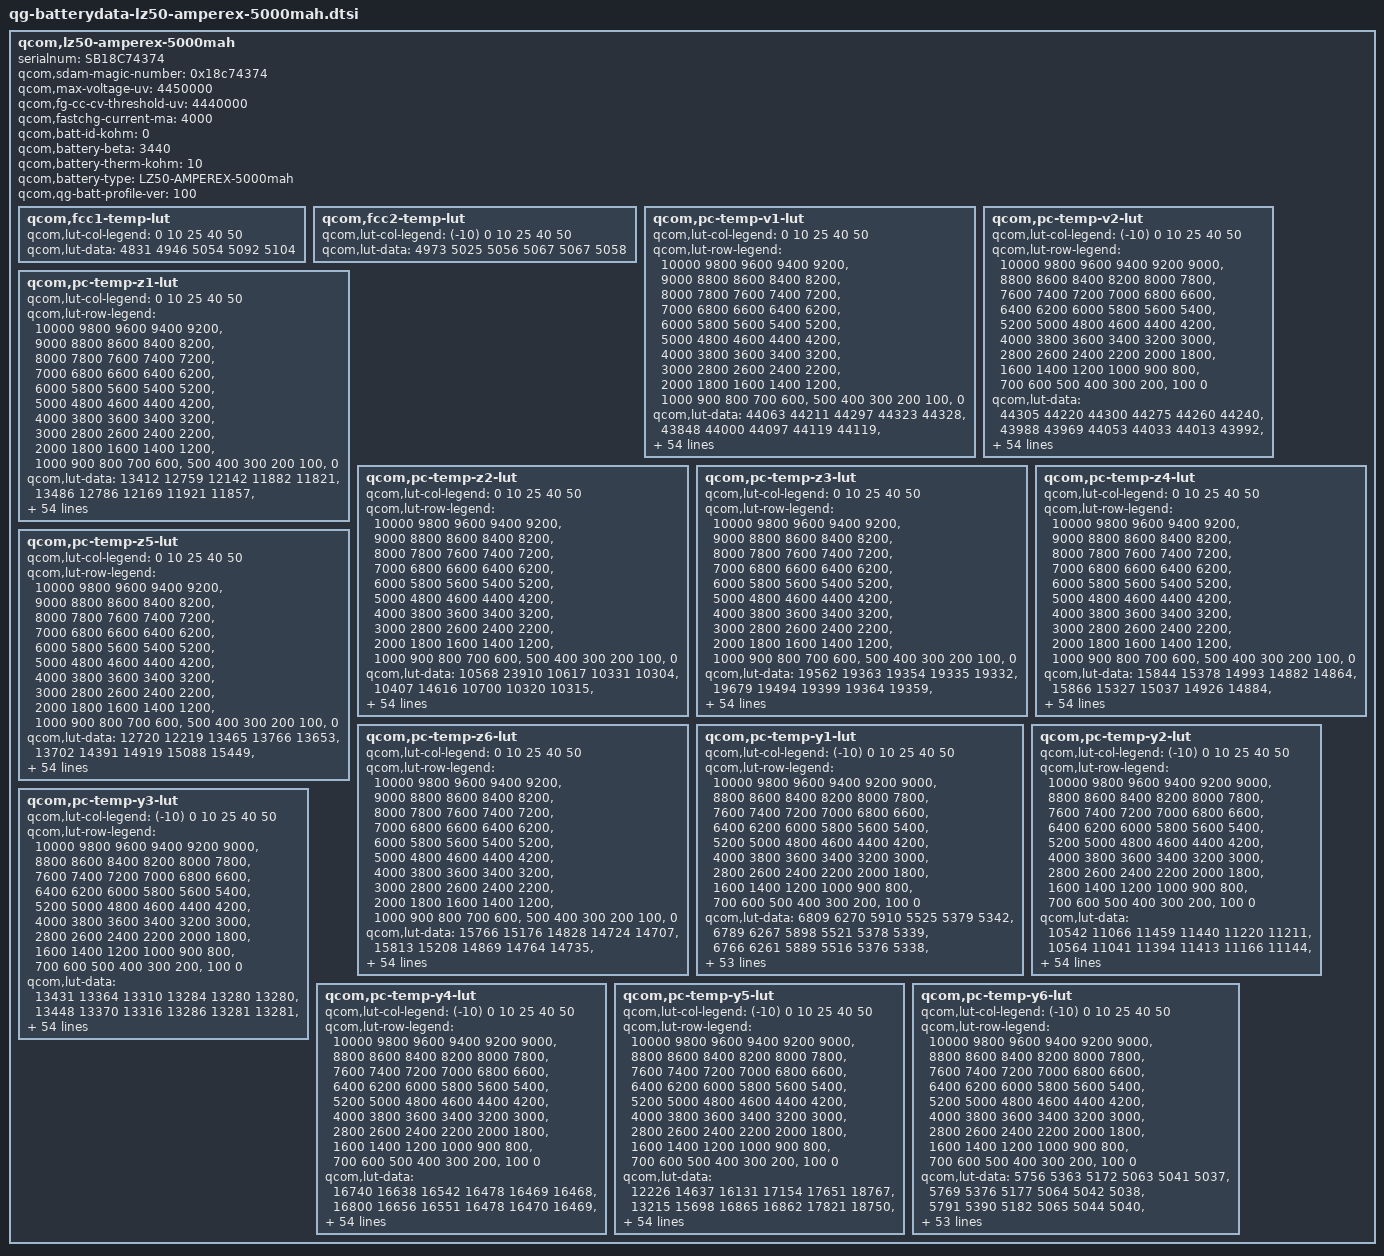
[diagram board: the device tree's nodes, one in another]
qcom,lz50-amperex-5000mah {
    /* 4458518_Lenovo_Nairobi_5000mAH_PM7250B_NEW4.45V_averaged_MasterSlave_Mar3th2020 */
    serialnum = "SB18C74374";
    qcom,sdam-magic-number = <0x18c74374>;
    qcom,max-voltage-uv = <4450000>;
    qcom,fg-cc-cv-threshold-uv = <4440000>;
    qcom,fastchg-current-ma = <4000>;
    qcom,batt-id-kohm = <0>;
    qcom,battery-beta = <3440>;
    qcom,battery-therm-kohm = <10>;
    qcom,battery-type = "LZ50-AMPEREX-5000mah";
    qcom,qg-batt-profile-ver = <100>;

	qcom,fcc1-temp-lut {
		qcom,lut-col-legend = <0 10 25 40 50>;
		qcom,lut-data = <4831 4946 5054 5092 5104>;
	};

	qcom,fcc2-temp-lut {
		qcom,lut-col-legend = <(-10) 0 10 25 40 50>;
		qcom,lut-data = <4973 5025 5056 5067 5067 5058>;
	};

	qcom,pc-temp-v1-lut {
		qcom,lut-col-legend = <0 10 25 40 50>;
		qcom,lut-row-legend = <10000 9800 9600 9400 9200>,
			<9000 8800 8600 8400 8200>,
			<8000 7800 7600 7400 7200>,
			<7000 6800 6600 6400 6200>,
			<6000 5800 5600 5400 5200>,
			<5000 4800 4600 4400 4200>,
			<4000 3800 3600 3400 3200>,
			<3000 2800 2600 2400 2200>,
			<2000 1800 1600 1400 1200>,
			<1000 900 800 700 600>,
			<500 400 300 200 100>,
			<0>;
		qcom,lut-data = <44063 44211 44297 44323 44328>,
			<43848 44000 44097 44119 44119>,
			<43627 43786 43898 43920 43917>,
			<43403 43569 43693 43715 43717>,
			<43171 43348 43475 43502 43508>,
			<42931 43117 43247 43284 43290>,
			<42691 42876 43011 43057 43065>,
			<42451 42633 42765 42818 42829>,
			<42211 42391 42519 42573 42587>,
			<41977 42149 42276 42333 42345>,
			<41747 41913 42035 42093 42101>,
			<41523 41680 41796 41854 41860>,
			<41305 41453 41561 41615 41623>,
			<41094 41233 41332 41380 41391>,
			<40887 41018 41111 41155 41167>,
			<40683 40811 40897 40936 40949>,
			<40485 40608 40690 40729 40739>,
			<40295 40413 40491 40531 40534>,
			<40112 40233 40301 40340 40339>,
			<39938 40060 40129 40160 40163>,
			<39781 39881 39951 39985 39994>,
			<39628 39696 39706 39769 39783>,
			<39456 39498 39391 39488 39487>,
			<39256 39255 39158 39243 39231>,
			<39063 38984 39019 39083 39086>,
			<38893 38813 38907 38954 38975>,
			<38740 38723 38800 38838 38858>,
			<38631 38652 38701 38735 38737>,
			<38557 38574 38607 38636 38626>,
			<38496 38498 38515 38535 38527>,
			<38440 38427 38430 38440 38438>,
			<38388 38360 38353 38357 38356>,
			<38341 38298 38281 38283 38282>,
			<38296 38243 38215 38214 38210>,
			<38254 38195 38157 38147 38137>,
			<38215 38149 38102 38082 38066>,
			<38179 38110 38051 38020 37995>,
			<38138 38068 38004 37960 37925>,
			<38076 38006 37940 37885 37841>,
			<37995 37920 37851 37785 37731>,
			<37896 37819 37748 37672 37608>,
			<37768 37699 37636 37559 37490>,
			<37621 37560 37508 37435 37364>,
			<37452 37392 37347 37273 37199>,
			<37317 37238 37198 37132 37064>,
			<37207 37137 37096 37043 36986>,
			<37166 37104 37068 37016 36957>,
			<37134 37089 37048 36994 36936>,
			<37105 37061 37030 36976 36914>,
			<37062 37024 36991 36927 36855>,
			<36912 36855 36792 36699 36603>,
			<36480 36417 36363 36263 36163>,
			<35895 35826 35785 35685 35585>,
			<35080 35000 34996 34896 34793>,
			<33673 33637 33769 33673 33565>,
			<30000 30000 30000 30000 30000>;
	};

	qcom,pc-temp-v2-lut {
		qcom,lut-col-legend = <(-10) 0 10 25 40 50>;
		qcom,lut-row-legend = <10000 9800 9600 9400 9200 9000>,
			<8800 8600 8400 8200 8000 7800>,
			<7600 7400 7200 7000 6800 6600>,
			<6400 6200 6000 5800 5600 5400>,
			<5200 5000 4800 4600 4400 4200>,
			<4000 3800 3600 3400 3200 3000>,
			<2800 2600 2400 2200 2000 1800>,
			<1600 1400 1200 1000 900 800>,
			<700 600 500 400 300 200>,
			<100 0>;
		qcom,lut-data = <44305 44220 44300 44275 44260 44240>,
			<43988 43969 44053 44033 44013 43992>,
			<43700 43729 43817 43798 43775 43754>,
			<43446 43500 43593 43573 43548 43527>,
			<43227 43286 43382 43358 43334 43313>,
			<43008 43065 43163 43136 43114 43094>,
			<42772 42826 42924 42898 42879 42862>,
			<42532 42580 42677 42655 42639 42623>,
			<42289 42335 42431 42411 42397 42383>,
			<42045 42089 42186 42165 42153 42140>,
			<41793 41850 41943 41922 41910 41899>,
			<41511 41618 41703 41683 41671 41660>,
			<41228 41392 41467 41447 41436 41426>,
			<41019 41173 41236 41216 41206 41196>,
			<40877 40961 41010 40989 40984 40972>,
			<40711 40739 40792 40770 40768 40755>,
			<40394 40497 40588 40559 40557 40547>,
			<39990 40244 40383 40356 40354 40347>,
			<39715 39989 40153 40167 40166 40161>,
			<39535 39727 39906 39988 39987 39984>,
			<39366 39488 39664 39783 39788 39788>,
			<39174 39280 39423 39529 39549 39551>,
			<38978 39092 39200 39279 39310 39313>,
			<38785 38922 39014 39070 39102 39108>,
			<38586 38766 38852 38885 38911 38919>,
			<38418 38622 38707 38732 38756 38763>,
			<38307 38491 38578 38608 38628 38635>,
			<38218 38368 38461 38498 38517 38523>,
			<38145 38248 38353 38394 38414 38416>,
			<38085 38131 38254 38297 38319 38318>,
			<38030 38036 38162 38208 38232 38229>,
			<37972 37963 38077 38126 38154 38151>,
			<37916 37903 37998 38050 38078 38075>,
			<37858 37853 37920 37983 38004 37998>,
			<37800 37812 37845 37920 37930 37919>,
			<37738 37770 37785 37850 37844 37826>,
			<37671 37728 37739 37774 37746 37710>,
			<37597 37681 37691 37693 37647 37596>,
			<37516 37618 37631 37608 37554 37498>,
			<37428 37539 37562 37519 37463 37407>,
			<37334 37441 37476 37428 37371 37316>,
			<37236 37308 37364 37334 37278 37227>,
			<37136 37164 37233 37214 37155 37103>,
			<37045 37014 37083 37074 37012 36949>,
			<36957 36893 36937 36956 36905 36850>,
			<36868 36806 36866 36899 36856 36800>,
			<36823 36771 36840 36886 36845 36791>,
			<36771 36730 36810 36868 36833 36777>,
			<36721 36676 36770 36848 36809 36751>,
			<36659 36580 36688 36791 36741 36671>,
			<36560 36333 36429 36563 36472 36363>,
			<36350 35851 35895 36067 35973 35863>,
			<35930 35143 35189 35418 35327 35208>,
			<35303 34140 34220 34507 34427 34300>,
			<34318 32755 32749 33178 33103 32919>,
			<33132 28650 27481 27771 27864 27950>;
	};

	qcom,pc-temp-z1-lut {
		qcom,lut-col-legend = <0 10 25 40 50>;
		qcom,lut-row-legend = <10000 9800 9600 9400 9200>,
			<9000 8800 8600 8400 8200>,
			<8000 7800 7600 7400 7200>,
			<7000 6800 6600 6400 6200>,
			<6000 5800 5600 5400 5200>,
			<5000 4800 4600 4400 4200>,
			<4000 3800 3600 3400 3200>,
			<3000 2800 2600 2400 2200>,
			<2000 1800 1600 1400 1200>,
			<1000 900 800 700 600>,
			<500 400 300 200 100>,
			<0>;
		qcom,lut-data = <13412 12759 12142 11882 11821>,
			<13486 12786 12169 11921 11857>,
			<13485 12797 12174 11930 11865>,
			<13479 12788 12175 11934 11870>,
			<13474 12772 12173 11935 11872>,
			<13466 12759 12168 11935 11873>,
			<13454 12748 12163 11935 11874>,
			<13434 12737 12156 11935 11876>,
			<13407 12728 12151 11935 11879>,
			<13390 12720 12148 11936 11882>,
			<13367 12715 12146 11939 11887>,
			<13350 12702 12146 11942 11891>,
			<13343 12691 12149 11945 11895>,
			<13326 12689 12150 11947 11898>,
			<13312 12686 12150 11948 11900>,
			<13291 12685 12149 11949 11902>,
			<13267 12682 12149 11950 11903>,
			<13251 12680 12150 11951 11905>,
			<13236 12677 12150 11953 11907>,
			<13230 12674 12153 11955 11910>,
			<13239 12674 12156 11957 11912>,
			<13254 12675 12157 11958 11913>,
			<13258 12678 12158 11959 11915>,
			<13259 12681 12160 11960 11916>,
			<13259 12686 12163 11962 11919>,
			<13259 12692 12169 11966 11922>,
			<13258 12700 12173 11969 11925>,
			<13258 12707 12177 11974 11929>,
			<13259 12709 12182 11978 11932>,
			<13262 12709 12187 11981 11936>,
			<13264 12711 12193 11985 11940>,
			<13268 12718 12199 11989 11944>,
			<13273 12728 12205 11994 11948>,
			<13290 12735 12211 12000 11952>,
			<13312 12741 12218 12005 11957>,
			<13319 12749 12224 12010 11962>,
			<13323 12759 12231 12014 11966>,
			<13328 12769 12238 12018 11969>,
			<13342 12778 12244 12022 11973>,
			<13368 12787 12250 12026 11976>,
			<13389 12796 12256 12030 11979>,
			<13404 12815 12264 12034 11982>,
			<13429 12837 12271 12038 11985>,
			<13482 12856 12279 12042 11989>,
			<13503 12877 12289 12047 11992>,
			<13497 12866 12297 12050 11994>,
			<13518 12865 12297 12051 11995>,
			<13485 12874 12295 12050 11995>,
			<13529 12871 12298 12051 11997>,
			<13520 12898 12308 12055 11999>,
			<13532 12898 12315 12060 12003>,
			<13562 12916 12328 12068 12010>,
			<13582 12959 12340 12078 12020>,
			<13616 12973 12365 12094 12035>,
			<13616 12973 12365 12094 12035>,
			<13616 12973 12365 12094 12035>;
	};

	qcom,pc-temp-z2-lut {
		qcom,lut-col-legend = <0 10 25 40 50>;
		qcom,lut-row-legend = <10000 9800 9600 9400 9200>,
			<9000 8800 8600 8400 8200>,
			<8000 7800 7600 7400 7200>,
			<7000 6800 6600 6400 6200>,
			<6000 5800 5600 5400 5200>,
			<5000 4800 4600 4400 4200>,
			<4000 3800 3600 3400 3200>,
			<3000 2800 2600 2400 2200>,
			<2000 1800 1600 1400 1200>,
			<1000 900 800 700 600>,
			<500 400 300 200 100>,
			<0>;
		qcom,lut-data = <10568 23910 10617 10331 10304>,
			<10407 14616 10700 10320 10315>,
			<10371 10559 11111 10418 10395>,
			<10347 10523 11352 10548 10485>,
			<10320 10499 11266 10556 10496>,
			<10292 10475 11090 10522 10471>,
			<10272 10450 10891 10487 10445>,
			<10259 10434 10628 10451 10424>,
			<10250 10425 10504 10421 10402>,
			<10248 10419 10626 10548 10380>,
			<10251 10419 10789 10873 10355>,
			<10255 10420 10757 10948 10347>,
			<10263 10423 10572 10658 10359>,
			<10278 10431 10491 10414 10374>,
			<10293 10447 10653 10410 10372>,
			<10306 10467 10860 10413 10364>,
			<10322 10496 10931 10475 10366>,
			<10345 10526 10972 10894 10401>,
			<10382 10551 10982 11198 10434>,
			<10417 10573 10808 10959 10412>,
			<10448 10579 10618 10566 10363>,
			<10476 10576 10631 10871 10373>,
			<10488 10574 10701 12811 10539>,
			<10493 10582 10728 14011 10663>,
			<10499 10604 10641 12626 10565>,
			<10507 10611 10544 10638 10389>,
			<10516 10597 10555 10358 10422>,
			<10524 10583 10611 10439 10834>,
			<10529 10588 10647 10515 11102>,
			<10534 10608 10668 10607 10955>,
			<10541 10619 10680 10697 10693>,
			<10552 10621 10674 10678 10533>,
			<10562 10623 10656 10563 10416>,
			<10570 10625 10645 10488 10334>,
			<10577 10627 10637 10461 10271>,
			<10585 10629 10632 10446 10231>,
			<10592 10634 10642 10463 10244>,
			<10600 10642 10671 10522 10309>,
			<10614 10655 10704 10586 10390>,
			<10633 10677 10749 10673 10529>,
			<10652 10697 10785 10735 10643>,
			<10670 10708 10797 10734 10661>,
			<10699 10722 10804 10728 10669>,
			<10766 10757 10812 10733 10680>,
			<10928 10967 10863 10722 10666>,
			<10936 11130 10928 10674 10529>,
			<10854 11157 10914 10589 10461>,
			<10782 11774 10906 10565 10469>,
			<10794 11874 10916 10607 10506>,
			<10689 11916 10982 10704 10605>,
			<10661 11929 10971 10609 10493>,
			<10573 11540 10906 10437 10234>,
			<10323 11311 10807 10297 10160>,
			<10164 11003 10728 10226 10078>,
			<10164 11003 10728 10226 10078>,
			<10164 11003 10728 10226 10078>;
	};

	qcom,pc-temp-z3-lut {
		qcom,lut-col-legend = <0 10 25 40 50>;
		qcom,lut-row-legend = <10000 9800 9600 9400 9200>,
			<9000 8800 8600 8400 8200>,
			<8000 7800 7600 7400 7200>,
			<7000 6800 6600 6400 6200>,
			<6000 5800 5600 5400 5200>,
			<5000 4800 4600 4400 4200>,
			<4000 3800 3600 3400 3200>,
			<3000 2800 2600 2400 2200>,
			<2000 1800 1600 1400 1200>,
			<1000 900 800 700 600>,
			<500 400 300 200 100>,
			<0>;
		qcom,lut-data = <19562 19363 19354 19335 19332>,
			<19679 19494 19399 19364 19359>,
			<19741 19565 19421 19385 19388>,
			<19780 19583 19438 19411 19404>,
			<19794 19594 19460 19422 19414>,
			<19800 19600 19480 19428 19421>,
			<19803 19603 19482 19433 19426>,
			<19803 19604 19477 19438 19431>,
			<19801 19601 19475 19442 19434>,
			<19800 19594 19484 19450 19435>,
			<19796 19588 19495 19458 19436>,
			<19790 19583 19489 19458 19435>,
			<19781 19578 19464 19444 19431>,
			<19770 19573 19450 19428 19424>,
			<19764 19568 19454 19421 19418>,
			<19765 19562 19459 19414 19411>,
			<19765 19556 19457 19410 19405>,
			<19760 19550 19452 19411 19400>,
			<19742 19543 19445 19411 19395>,
			<19729 19537 19431 19402 19386>,
			<19726 19535 19419 19388 19377>,
			<19725 19545 19425 19384 19375>,
			<19727 19557 19447 19387 19379>,
			<19739 19567 19456 19389 19383>,
			<19749 19576 19438 19377 19369>,
			<19749 19578 19416 19359 19345>,
			<19748 19565 19408 19356 19348>,
			<19746 19551 19403 19358 19401>,
			<19738 19546 19401 19362 19437>,
			<19728 19543 19407 19388 19435>,
			<19720 19543 19415 19419 19429>,
			<19713 19547 19424 19422 19422>,
			<19708 19552 19433 19416 19411>,
			<19704 19552 19436 19409 19399>,
			<19701 19551 19435 19401 19387>,
			<19698 19550 19433 19391 19377>,
			<19695 19548 19429 19383 19369>,
			<19691 19545 19422 19375 19362>,
			<19685 19542 19419 19373 19360>,
			<19677 19537 19418 19374 19360>,
			<19669 19532 19417 19375 19360>,
			<19659 19526 19412 19375 19362>,
			<19645 19519 19406 19373 19368>,
			<19622 19509 19402 19377 19376>,
			<19386 19473 19393 19376 19375>,
			<19307 19439 19384 19363 19359>,
			<19304 19429 19379 19351 19348>,
			<19298 19299 19376 19349 19337>,
			<19294 19291 19363 19339 19331>,
			<19293 19285 19355 19333 19327>,
			<19293 19296 19372 19349 19343>,
			<19303 19309 19379 19380 19370>,
			<19311 19322 19383 19379 19371>,
			<19327 19384 19387 19380 19375>,
			<19327 19384 19387 19380 19375>,
			<19327 19384 19387 19380 19375>;
	};

	qcom,pc-temp-z4-lut {
		qcom,lut-col-legend = <0 10 25 40 50>;
		qcom,lut-row-legend = <10000 9800 9600 9400 9200>,
			<9000 8800 8600 8400 8200>,
			<8000 7800 7600 7400 7200>,
			<7000 6800 6600 6400 6200>,
			<6000 5800 5600 5400 5200>,
			<5000 4800 4600 4400 4200>,
			<4000 3800 3600 3400 3200>,
			<3000 2800 2600 2400 2200>,
			<2000 1800 1600 1400 1200>,
			<1000 900 800 700 600>,
			<500 400 300 200 100>,
			<0>;
		qcom,lut-data = <15844 15378 14993 14882 14864>,
			<15866 15327 15037 14926 14884>,
			<15745 15267 14997 14914 14880>,
			<15556 15190 14949 14889 14864>,
			<15423 15106 14902 14866 14847>,
			<15316 15040 14860 14842 14827>,
			<15228 14986 14838 14819 14807>,
			<15156 14942 14824 14800 14789>,
			<15096 14908 14810 14780 14772>,
			<15046 14881 14775 14751 14755>,
			<15002 14857 14736 14717 14739>,
			<14966 14837 14729 14704 14727>,
			<14939 14819 14735 14709 14718>,
			<14917 14802 14735 14713 14711>,
			<14896 14787 14716 14711 14707>,
			<14870 14776 14693 14707 14705>,
			<14849 14767 14685 14700 14701>,
			<14841 14761 14681 14682 14697>,
			<14837 14755 14678 14669 14693>,
			<14831 14751 14683 14670 14690>,
			<14808 14748 14694 14679 14687>,
			<14778 14746 14721 14696 14693>,
			<14773 14745 14782 14753 14760>,
			<14788 14770 14822 14805 14821>,
			<14807 14834 14840 14832 14836>,
			<14830 14858 14849 14850 14845>,
			<14855 14852 14847 14850 14835>,
			<14863 14841 14835 14834 14764>,
			<14858 14830 14820 14811 14711>,
			<14849 14816 14800 14768 14702>,
			<14840 14801 14778 14722 14696>,
			<14828 14784 14755 14706 14692>,
			<14817 14768 14733 14697 14687>,
			<14806 14757 14718 14693 14685>,
			<14794 14749 14708 14691 14685>,
			<14784 14742 14703 14690 14684>,
			<14773 14735 14701 14690 14684>,
			<14763 14730 14700 14690 14683>,
			<14754 14728 14701 14690 14684>,
			<14745 14727 14707 14700 14698>,
			<14736 14725 14712 14710 14712>,
			<14728 14717 14710 14708 14707>,
			<14719 14707 14708 14703 14696>,
			<14708 14699 14705 14701 14696>,
			<14857 14681 14691 14691 14689>,
			<14913 14676 14671 14673 14669>,
			<14913 14678 14666 14678 14673>,
			<14915 14816 14654 14666 14668>,
			<14915 14820 14651 14653 14651>,
			<14910 14823 14652 14644 14638>,
			<14906 14814 14654 14663 14667>,
			<14918 14816 14667 14659 14669>,
			<14923 14812 14668 14667 14676>,
			<14931 14758 14669 14670 14677>,
			<14931 14758 14669 14670 14677>,
			<14931 14758 14669 14670 14677>;
	};

	qcom,pc-temp-z5-lut {
		qcom,lut-col-legend = <0 10 25 40 50>;
		qcom,lut-row-legend = <10000 9800 9600 9400 9200>,
			<9000 8800 8600 8400 8200>,
			<8000 7800 7600 7400 7200>,
			<7000 6800 6600 6400 6200>,
			<6000 5800 5600 5400 5200>,
			<5000 4800 4600 4400 4200>,
			<4000 3800 3600 3400 3200>,
			<3000 2800 2600 2400 2200>,
			<2000 1800 1600 1400 1200>,
			<1000 900 800 700 600>,
			<500 400 300 200 100>,
			<0>;
		qcom,lut-data = <12720 12219 13465 13766 13653>,
			<13702 14391 14919 15088 15449>,
			<14339 15698 15683 16499 17678>,
			<14837 16198 16331 18254 19178>,
			<15243 16541 17411 19083 20295>,
			<15562 16948 18592 19545 21140>,
			<15894 17415 19061 20042 22025>,
			<16305 17839 19304 20796 23113>,
			<16775 18167 19624 21824 24284>,
			<17297 18463 22025 24177 25594>,
			<17912 18830 24905 27887 27230>,
			<18525 19302 24701 29049 28711>,
			<19011 19848 22588 27310 30133>,
			<19442 20463 21605 25803 31114>,
			<20115 21163 24131 25845 31090>,
			<21865 21938 27699 26041 30776>,
			<23548 22958 29310 27003 30797>,
			<23763 23706 30335 30821 32108>,
			<23664 23773 30709 33690 33341>,
			<23621 23649 28174 32058 32794>,
			<25288 24066 25495 29067 31608>,
			<29061 28972 30028 29094 31488>,
			<34120 35195 44125 30734 32532>,
			<43090 39493 49979 31816 32771>,
			<49235 43396 38533 27314 27268>,
			<48960 44144 24809 19647 18572>,
			<47580 37180 21199 17390 17980>,
			<45700 29438 19407 16731 25963>,
			<41886 27492 18948 16546 32190>,
			<38063 26514 19336 20259 33201>,
			<36375 26306 20095 25617 33150>,
			<35246 27933 21599 27316 32237>,
			<34849 30388 24332 28094 30962>,
			<35192 32347 27029 28419 29801>,
			<35823 34336 30122 28545 28688>,
			<36405 35791 32263 28609 27858>,
			<37123 36928 32572 28532 27642>,
			<37856 37732 32682 28285 27553>,
			<38833 37839 32748 28250 27549>,
			<39943 37637 32809 29282 27726>,
			<40158 37287 32783 30263 27900>,
			<39152 36230 30399 28259 27521>,
			<38082 35157 26948 24800 26813>,
			<37022 34628 26662 27218 30735>,
			<18425 34080 27594 28400 32321>,
			<12720 28098 28184 25227 25615>,
			<12589 25496 26086 20797 20759>,
			<12419 12685 26593 21526 18845>,
			<12324 12448 22891 21445 20182>,
			<12318 12310 21364 22307 22825>,
			<12441 12709 25154 23609 23796>,
			<12520 12986 21342 25363 23502>,
			<12517 13249 20910 22007 20409>,
			<12862 17533 20320 19796 18684>,
			<12862 17533 20320 19796 18684>,
			<12862 17533 20320 19796 18684>;
	};

	qcom,pc-temp-z6-lut {
		qcom,lut-col-legend = <0 10 25 40 50>;
		qcom,lut-row-legend = <10000 9800 9600 9400 9200>,
			<9000 8800 8600 8400 8200>,
			<8000 7800 7600 7400 7200>,
			<7000 6800 6600 6400 6200>,
			<6000 5800 5600 5400 5200>,
			<5000 4800 4600 4400 4200>,
			<4000 3800 3600 3400 3200>,
			<3000 2800 2600 2400 2200>,
			<2000 1800 1600 1400 1200>,
			<1000 900 800 700 600>,
			<500 400 300 200 100>,
			<0>;
		qcom,lut-data = <15766 15176 14828 14724 14707>,
			<15813 15208 14869 14764 14735>,
			<15770 15219 14864 14772 14748>,
			<15698 15198 14859 14776 14752>,
			<15637 15155 14852 14774 14752>,
			<15581 15122 14842 14767 14748>,
			<15530 15095 14833 14760 14743>,
			<15488 15071 14823 14754 14738>,
			<15451 15049 14814 14749 14733>,
			<15418 15030 14804 14742 14728>,
			<15389 15013 14794 14734 14723>,
			<15364 14998 14785 14728 14718>,
			<15341 14984 14776 14721 14712>,
			<15320 14973 14768 14715 14706>,
			<15302 14962 14761 14710 14701>,
			<15286 14953 14755 14705 14696>,
			<15271 14944 14750 14699 14691>,
			<15256 14936 14745 14693 14687>,
			<15242 14930 14741 14688 14682>,
			<15229 14925 14737 14683 14676>,
			<15215 14924 14734 14679 14669>,
			<15202 14927 14746 14683 14671>,
			<15202 14935 14788 14714 14705>,
			<15215 14954 14806 14738 14731>,
			<15230 14987 14804 14739 14728>,
			<15242 14998 14800 14738 14722>,
			<15253 14990 14795 14735 14719>,
			<15256 14979 14789 14730 14717>,
			<15251 14972 14783 14725 14715>,
			<15244 14966 14779 14722 14712>,
			<15237 14961 14774 14718 14706>,
			<15230 14958 14770 14714 14701>,
			<15224 14954 14766 14708 14694>,
			<15219 14952 14762 14703 14688>,
			<15215 14949 14759 14698 14682>,
			<15212 14947 14756 14694 14677>,
			<15210 14946 14753 14689 14672>,
			<15209 14945 14750 14685 14668>,
			<15209 14945 14750 14684 14667>,
			<15211 14947 14753 14689 14673>,
			<15213 14948 14755 14694 14679>,
			<15215 14946 14754 14693 14678>,
			<15216 14943 14750 14690 14677>,
			<15212 14941 14749 14692 14681>,
			<15173 14923 14740 14688 14678>,
			<15160 14907 14728 14674 14662>,
			<15159 14903 14723 14670 14658>,
			<15158 14897 14716 14663 14650>,
			<15158 14897 14709 14653 14639>,
			<15162 14899 14707 14645 14631>,
			<15171 14907 14718 14663 14653>,
			<15189 14922 14730 14680 14671>,
			<15207 14934 14736 14685 14677>,
			<15238 14955 14743 14691 14684>,
			<15238 14955 14743 14691 14684>,
			<15238 14955 14743 14691 14684>;
	};

	qcom,pc-temp-y1-lut {
		qcom,lut-col-legend = <(-10) 0 10 25 40 50>;
		qcom,lut-row-legend = <10000 9800 9600 9400 9200 9000>,
			<8800 8600 8400 8200 8000 7800>,
			<7600 7400 7200 7000 6800 6600>,
			<6400 6200 6000 5800 5600 5400>,
			<5200 5000 4800 4600 4400 4200>,
			<4000 3800 3600 3400 3200 3000>,
			<2800 2600 2400 2200 2000 1800>,
			<1600 1400 1200 1000 900 800>,
			<700 600 500 400 300 200>,
			<100 0>;
		qcom,lut-data = <6809 6270 5910 5525 5379 5342>,
			<6789 6267 5898 5521 5378 5339>,
			<6766 6261 5889 5516 5376 5338>,
			<6745 6255 5882 5512 5374 5337>,
			<6730 6249 5878 5508 5373 5337>,
			<6724 6245 5876 5505 5372 5337>,
			<6727 6241 5877 5503 5371 5337>,
			<6733 6237 5880 5501 5371 5338>,
			<6737 6237 5879 5500 5371 5338>,
			<6742 6238 5877 5499 5370 5338>,
			<6747 6239 5875 5498 5370 5338>,
			<6751 6240 5868 5497 5371 5338>,
			<6757 6242 5862 5496 5371 5339>,
			<6759 6242 5861 5496 5371 5340>,
			<6759 6241 5861 5496 5372 5341>,
			<6760 6241 5862 5497 5372 5341>,
			<6763 6244 5862 5498 5373 5342>,
			<6766 6247 5863 5499 5374 5343>,
			<6766 6248 5864 5500 5376 5344>,
			<6758 6248 5865 5501 5378 5346>,
			<6751 6249 5866 5503 5380 5348>,
			<6759 6246 5867 5505 5381 5349>,
			<6772 6243 5867 5508 5381 5351>,
			<6775 6246 5869 5511 5383 5352>,
			<6777 6253 5872 5514 5385 5353>,
			<6778 6256 5873 5516 5386 5354>,
			<6772 6252 5875 5519 5388 5356>,
			<6761 6246 5876 5522 5390 5358>,
			<6754 6244 5877 5525 5392 5360>,
			<6750 6242 5879 5528 5395 5363>,
			<6748 6242 5880 5531 5398 5365>,
			<6751 6246 5882 5535 5400 5367>,
			<6755 6250 5883 5538 5403 5369>,
			<6756 6250 5885 5541 5405 5371>,
			<6759 6249 5888 5544 5407 5373>,
			<6761 6250 5891 5547 5409 5375>,
			<6765 6254 5897 5550 5410 5376>,
			<6772 6260 5901 5552 5411 5378>,
			<6774 6265 5906 5552 5412 5379>,
			<6772 6272 5910 5552 5413 5381>,
			<6770 6274 5911 5553 5414 5382>,
			<6769 6268 5906 5555 5415 5383>,
			<6769 6267 5908 5558 5416 5384>,
			<6768 6271 5917 5561 5418 5385>,
			<6778 6274 5940 5565 5420 5387>,
			<6836 6305 5949 5569 5423 5390>,
			<6859 6314 5942 5570 5424 5390>,
			<6855 6314 5953 5570 5424 5390>,
			<6855 6322 5956 5571 5425 5391>,
			<6883 6324 5959 5572 5425 5392>,
			<6916 6334 5972 5573 5427 5395>,
			<6981 6412 5991 5579 5432 5399>,
			<7110 6503 6010 5591 5440 5406>,
			<7322 6717 6073 5605 5450 5417>,
			<7322 6717 6073 5605 5450 5417>,
			<7322 6717 6073 5605 5450 5417>;
	};

	qcom,pc-temp-y2-lut {
		qcom,lut-col-legend = <(-10) 0 10 25 40 50>;
		qcom,lut-row-legend = <10000 9800 9600 9400 9200 9000>,
			<8800 8600 8400 8200 8000 7800>,
			<7600 7400 7200 7000 6800 6600>,
			<6400 6200 6000 5800 5600 5400>,
			<5200 5000 4800 4600 4400 4200>,
			<4000 3800 3600 3400 3200 3000>,
			<2800 2600 2400 2200 2000 1800>,
			<1600 1400 1200 1000 900 800>,
			<700 600 500 400 300 200>,
			<100 0>;
		qcom,lut-data = <10542 11066 11459 11440 11220 11211>,
			<10564 11041 11394 11413 11166 11144>,
			<10605 11015 11331 11378 11110 11062>,
			<10652 10990 11272 11341 11057 10980>,
			<10691 10969 11221 11304 11009 10911>,
			<10710 10955 11179 11272 10970 10872>,
			<10711 10946 11143 11239 10934 10854>,
			<10712 10940 11115 11208 10905 10841>,
			<10709 10939 11093 11184 10888 10826>,
			<10694 10940 11075 11164 10875 10798>,
			<10684 10943 11069 11152 10871 10783>,
			<10754 10953 11071 11142 10877 10786>,
			<10875 10973 11077 11135 10887 10792>,
			<10903 11001 11091 11136 10890 10795>,
			<10898 11045 11126 11141 10890 10795>,
			<10894 11078 11163 11149 10900 10801>,
			<10905 11092 11201 11173 10937 10823>,
			<10932 11103 11236 11211 10990 10857>,
			<10958 11124 11258 11272 11042 10898>,
			<10987 11157 11274 11358 11100 10954>,
			<11005 11189 11292 11394 11169 11023>,
			<11004 11214 11317 11401 11283 11140>,
			<11000 11236 11346 11406 11364 11228>,
			<10918 11254 11374 11411 11336 11207>,
			<10293 11271 11403 11418 11268 11144>,
			<9767 11283 11426 11427 11242 11124>,
			<9725 11290 11447 11451 11248 11152>,
			<9708 11297 11461 11477 11266 11191>,
			<9698 11311 11468 11502 11321 11216>,
			<9692 11335 11474 11530 11415 11241>,
			<9687 11351 11477 11552 11463 11289>,
			<9682 11361 11481 11585 11483 11431>,
			<9678 11366 11485 11606 11502 11552>,
			<9674 11342 11489 11614 11532 11583>,
			<9671 11262 11493 11621 11562 11602>,
			<9669 11183 11491 11617 11550 11588>,
			<9667 11118 11464 11595 11454 11474>,
			<9666 11050 11429 11567 11390 11375>,
			<9665 10979 11397 11523 11389 11347>,
			<9664 10901 11360 11480 11389 11330>,
			<9663 10746 11315 11476 11387 11324>,
			<9662 10149 11258 11489 11369 11331>,
			<9662 9783 11187 11487 11333 11294>,
			<9661 9719 11095 11478 11266 11179>,
			<9660 9692 10987 11478 11169 11016>,
			<9659 9681 10962 11379 11050 10907>,
			<9659 9674 10879 11326 11052 10949>,
			<9658 9669 10816 11287 11071 10981>,
			<9657 9665 10728 11287 11082 10968>,
			<9656 9661 10651 11316 11080 10975>,
			<9653 9657 10496 11316 11035 10854>,
			<9649 9652 10039 11251 10948 10806>,
			<9648 9650 9684 11154 10833 10671>,
			<9648 9649 9655 10989 10671 10534>,
			<9648 9649 9655 10989 10671 10534>,
			<9648 9649 9655 10989 10671 10534>;
	};

	qcom,pc-temp-y3-lut {
		qcom,lut-col-legend = <(-10) 0 10 25 40 50>;
		qcom,lut-row-legend = <10000 9800 9600 9400 9200 9000>,
			<8800 8600 8400 8200 8000 7800>,
			<7600 7400 7200 7000 6800 6600>,
			<6400 6200 6000 5800 5600 5400>,
			<5200 5000 4800 4600 4400 4200>,
			<4000 3800 3600 3400 3200 3000>,
			<2800 2600 2400 2200 2000 1800>,
			<1600 1400 1200 1000 900 800>,
			<700 600 500 400 300 200>,
			<100 0>;
		qcom,lut-data = <13431 13364 13310 13284 13280 13280>,
			<13448 13370 13316 13286 13281 13281>,
			<13469 13379 13322 13288 13282 13281>,
			<13491 13389 13327 13290 13284 13282>,
			<13509 13398 13332 13291 13285 13283>,
			<13520 13402 13333 13291 13286 13284>,
			<13524 13403 13332 13291 13286 13285>,
			<13527 13404 13331 13291 13287 13286>,
			<13527 13404 13331 13292 13287 13286>,
			<13523 13403 13334 13294 13288 13287>,
			<13517 13402 13336 13296 13288 13287>,
			<13510 13401 13337 13298 13289 13288>,
			<13502 13400 13338 13300 13289 13288>,
			<13494 13401 13338 13301 13290 13288>,
			<13484 13406 13339 13300 13294 13288>,
			<13474 13408 13339 13300 13296 13289>,
			<13463 13401 13342 13302 13296 13291>,
			<13452 13389 13345 13305 13297 13294>,
			<13449 13383 13344 13305 13298 13296>,
			<13448 13379 13340 13305 13299 13298>,
			<13447 13375 13336 13304 13299 13299>,
			<13443 13370 13332 13303 13296 13295>,
			<13433 13366 13327 13300 13291 13289>,
			<13420 13363 13324 13296 13288 13285>,
			<13399 13360 13320 13290 13285 13282>,
			<13385 13358 13319 13288 13283 13281>,
			<13384 13355 13318 13289 13282 13281>,
			<13384 13353 13318 13291 13282 13282>,
			<13386 13348 13317 13291 13282 13281>,
			<13400 13339 13317 13291 13282 13279>,
			<13419 13333 13317 13291 13282 13279>,
			<13438 13330 13317 13291 13282 13279>,
			<13460 13328 13317 13292 13282 13280>,
			<13488 13330 13316 13292 13283 13281>,
			<13526 13337 13314 13293 13283 13283>,
			<13571 13345 13314 13293 13284 13283>,
			<13618 13354 13316 13293 13283 13282>,
			<13669 13362 13318 13292 13282 13281>,
			<13725 13368 13320 13292 13283 13281>,
			<13789 13372 13322 13291 13284 13283>,
			<13855 13376 13323 13291 13285 13284>,
			<13919 13379 13325 13291 13286 13286>,
			<13987 13385 13326 13291 13285 13285>,
			<14071 13415 13327 13289 13282 13280>,
			<14172 13453 13325 13288 13281 13282>,
			<14245 13470 13326 13289 13289 13287>,
			<14289 13518 13331 13294 13293 13292>,
			<14404 13582 13337 13299 13297 13294>,
			<14567 13688 13347 13306 13299 13295>,
			<14798 13878 13363 13307 13298 13294>,
			<15459 14252 13374 13303 13293 13289>,
			<18231 15579 13391 13299 13291 13289>,
			<27781 21530 13563 13303 13295 13292>,
			<65535 44415 14908 13310 13304 13302>,
			<65535 44415 14908 13310 13304 13302>,
			<65535 44415 14908 13310 13304 13302>;
	};

	qcom,pc-temp-y4-lut {
		qcom,lut-col-legend = <(-10) 0 10 25 40 50>;
		qcom,lut-row-legend = <10000 9800 9600 9400 9200 9000>,
			<8800 8600 8400 8200 8000 7800>,
			<7600 7400 7200 7000 6800 6600>,
			<6400 6200 6000 5800 5600 5400>,
			<5200 5000 4800 4600 4400 4200>,
			<4000 3800 3600 3400 3200 3000>,
			<2800 2600 2400 2200 2000 1800>,
			<1600 1400 1200 1000 900 800>,
			<700 600 500 400 300 200>,
			<100 0>;
		qcom,lut-data = <16740 16638 16542 16478 16469 16468>,
			<16800 16656 16551 16478 16470 16469>,
			<16890 16692 16559 16479 16470 16471>,
			<16987 16735 16566 16481 16471 16473>,
			<17068 16770 16573 16484 16473 16475>,
			<17110 16785 16579 16486 16474 16476>,
			<17120 16786 16583 16491 16475 16476>,
			<17125 16786 16587 16496 16477 16475>,
			<17134 16789 16590 16499 16479 16476>,
			<17146 16797 16594 16501 16481 16477>,
			<17153 16808 16599 16502 16484 16479>,
			<17142 16826 16609 16505 16488 16481>,
			<17124 16848 16623 16510 16493 16484>,
			<17136 16867 16640 16517 16495 16487>,
			<17246 16887 16661 16529 16497 16492>,
			<17327 16896 16685 16541 16500 16496>,
			<17206 16890 16720 16554 16507 16499>,
			<16979 16877 16747 16568 16517 16503>,
			<16907 16844 16739 16596 16535 16513>,
			<16899 16763 16701 16636 16561 16531>,
			<16890 16703 16660 16646 16569 16538>,
			<16853 16678 16610 16599 16555 16531>,
			<16801 16660 16568 16542 16535 16520>,
			<16788 16644 16550 16512 16510 16503>,
			<16793 16631 16539 16488 16481 16480>,
			<16799 16620 16535 16483 16473 16473>,
			<16806 16610 16533 16484 16475 16474>,
			<16813 16601 16533 16485 16479 16475>,
			<16817 16591 16534 16488 16484 16479>,
			<16818 16579 16536 16494 16492 16488>,
			<16820 16575 16537 16501 16501 16497>,
			<16824 16579 16537 16507 16513 16506>,
			<16832 16587 16537 16514 16522 16514>,
			<16838 16595 16533 16523 16525 16520>,
			<16843 16604 16526 16532 16527 16524>,
			<16846 16616 16525 16532 16525 16523>,
			<16849 16635 16532 16522 16512 16505>,
			<16852 16655 16542 16510 16500 16492>,
			<16852 16672 16551 16499 16494 16492>,
			<16848 16687 16561 16489 16490 16494>,
			<16844 16704 16568 16489 16491 16498>,
			<16841 16731 16573 16494 16497 16510>,
			<16840 16740 16576 16492 16492 16505>,
			<16843 16718 16577 16481 16471 16471>,
			<16857 16712 16569 16469 16459 16454>,
			<16862 16710 16559 16477 16467 16479>,
			<16855 16724 16576 16491 16497 16515>,
			<16873 16749 16601 16516 16536 16558>,
			<16893 16789 16638 16555 16579 16599>,
			<16914 16838 16684 16583 16597 16609>,
			<16968 16852 16689 16545 16525 16513>,
			<17310 16939 16699 16492 16484 16489>,
			<18791 18479 16782 16495 16486 16489>,
			<29455 38235 17022 16515 16492 16492>,
			<29455 38235 17022 16515 16492 16492>,
			<29455 38235 17022 16515 16492 16492>;
	};

	qcom,pc-temp-y5-lut {
		qcom,lut-col-legend = <(-10) 0 10 25 40 50>;
		qcom,lut-row-legend = <10000 9800 9600 9400 9200 9000>,
			<8800 8600 8400 8200 8000 7800>,
			<7600 7400 7200 7000 6800 6600>,
			<6400 6200 6000 5800 5600 5400>,
			<5200 5000 4800 4600 4400 4200>,
			<4000 3800 3600 3400 3200 3000>,
			<2800 2600 2400 2200 2000 1800>,
			<1600 1400 1200 1000 900 800>,
			<700 600 500 400 300 200>,
			<100 0>;
		qcom,lut-data = <12226 14637 16131 17154 17651 18767>,
			<13215 15698 16865 16862 17821 18750>,
			<14204 16531 17301 16548 17836 18564>,
			<15129 17131 17513 16230 17732 18302>,
			<15930 17493 17572 15928 17539 18057>,
			<16542 17611 17546 15660 17292 17923>,
			<17047 17411 16787 15121 16925 17787>,
			<17424 17035 15689 14513 16497 17596>,
			<17472 16695 15329 14421 16137 17369>,
			<17337 16299 15227 14729 15783 16892>,
			<17119 16111 15209 14911 15428 16448>,
			<16480 16165 14942 14979 14986 16046>,
			<15612 16296 14602 14968 14649 15631>,
			<15724 16538 14546 14637 14809 15231>,
			<17769 17104 14527 14073 15408 14813>,
			<19293 17862 14626 13854 15647 14674>,
			<18742 19300 15450 13875 15213 15036>,
			<17712 20697 16789 13925 14724 15452>,
			<17680 20867 18460 14136 14619 15485>,
			<19348 20820 20582 14786 14577 15417>,
			<20690 20769 21396 15920 14769 15507>,
			<20743 20735 21412 19442 17338 17297>,
			<20652 20723 21355 22381 19722 19082>,
			<20003 20748 20955 21202 19635 19092>,
			<16138 20783 20125 18205 19132 18781>,
			<12777 20796 19860 17329 18600 18435>,
			<12191 20746 19976 18110 17725 17970>,
			<11873 20623 20109 18865 16961 17406>,
			<11823 19946 20323 19015 16652 16513>,
			<11952 17903 20767 19108 16449 15361>,
			<12104 16345 21226 19262 16360 15051>,
			<12187 15405 22108 19526 16368 15277>,
			<12255 14809 22748 19876 16466 15680>,
			<12369 14977 22127 20444 17154 16743>,
			<12610 15818 20873 21247 18287 18308>,
			<12847 16736 20607 22032 18847 18871>,
			<12986 17977 21033 22930 19114 18991>,
			<13093 18958 21347 23372 19404 19130>,
			<13143 19027 21206 22629 20038 19547>,
			<13134 18952 20854 21279 20667 20206>,
			<13088 18679 20380 20450 20731 20918>,
			<12911 15990 19479 19899 20583 21735>,
			<12644 14128 18739 19569 20240 21370>,
			<12567 13778 18089 19132 19659 20079>,
			<12481 13417 16963 18604 18350 20887>,
			<12313 12886 17201 16803 18362 17464>,
			<12422 13019 16851 17490 17732 16857>,
			<12382 12989 16220 17311 17186 15808>,
			<12645 12970 16109 18264 16496 15279>,
			<12880 13167 16542 18154 16026 15028>,
			<12807 13265 16506 18000 16101 15396>,
			<11452 12454 14651 18794 16760 15756>,
			<9765 10083 13458 19313 16993 15389>,
			<9134 8969 12895 21056 21054 19246>,
			<9134 8969 12895 21056 21054 19246>,
			<9134 8969 12895 21056 21054 19246>;
	};

	qcom,pc-temp-y6-lut {
		qcom,lut-col-legend = <(-10) 0 10 25 40 50>;
		qcom,lut-row-legend = <10000 9800 9600 9400 9200 9000>,
			<8800 8600 8400 8200 8000 7800>,
			<7600 7400 7200 7000 6800 6600>,
			<6400 6200 6000 5800 5600 5400>,
			<5200 5000 4800 4600 4400 4200>,
			<4000 3800 3600 3400 3200 3000>,
			<2800 2600 2400 2200 2000 1800>,
			<1600 1400 1200 1000 900 800>,
			<700 600 500 400 300 200>,
			<100 0>;
		qcom,lut-data = <5756 5363 5172 5063 5041 5037>,
			<5769 5376 5177 5064 5042 5038>,
			<5791 5390 5182 5065 5044 5040>,
			<5817 5401 5186 5066 5045 5041>,
			<5839 5409 5189 5067 5046 5042>,
			<5849 5412 5190 5069 5047 5043>,
			<5850 5409 5189 5070 5048 5044>,
			<5851 5405 5187 5071 5049 5044>,
			<5850 5403 5187 5072 5050 5045>,
			<5847 5401 5189 5074 5051 5046>,
			<5843 5401 5191 5076 5052 5047>,
			<5833 5402 5193 5078 5054 5048>,
			<5820 5406 5196 5081 5055 5049>,
			<5821 5411 5201 5084 5057 5051>,
			<5848 5418 5206 5087 5060 5052>,
			<5869 5421 5213 5090 5063 5054>,
			<5833 5416 5224 5095 5065 5056>,
			<5767 5405 5233 5100 5068 5059>,
			<5751 5390 5230 5109 5074 5064>,
			<5753 5365 5216 5120 5082 5071>,
			<5755 5347 5202 5123 5085 5073>,
			<5751 5337 5185 5108 5078 5068>,
			<5740 5330 5170 5090 5069 5060>,
			<5730 5326 5162 5078 5059 5052>,
			<5717 5322 5157 5067 5048 5043>,
			<5710 5320 5156 5065 5045 5041>,
			<5715 5319 5156 5066 5046 5041>,
			<5730 5317 5156 5067 5046 5042>,
			<5747 5315 5157 5069 5048 5043>,
			<5769 5310 5158 5071 5050 5045>,
			<5796 5309 5160 5073 5053 5047>,
			<5824 5312 5162 5076 5056 5050>,
			<5856 5319 5163 5078 5059 5053>,
			<5892 5328 5162 5082 5061 5056>,
			<5934 5344 5161 5085 5063 5058>,
			<5978 5363 5161 5085 5062 5058>,
			<6024 5387 5165 5083 5057 5052>,
			<6073 5415 5172 5080 5054 5048>,
			<6124 5445 5178 5076 5053 5048>,
			<6176 5477 5185 5073 5053 5050>,
			<6229 5509 5192 5073 5054 5052>,
			<6285 5537 5199 5075 5056 5057>,
			<6344 5569 5207 5074 5054 5055>,
			<6416 5607 5216 5070 5047 5042>,
			<6505 5664 5221 5067 5043 5039>,
			<6581 5706 5223 5071 5051 5051>,
			<6624 5769 5239 5079 5063 5065>,
			<6730 5851 5261 5089 5077 5078>,
			<6873 5970 5293 5105 5091 5091>,
			<7081 6157 5336 5115 5096 5094>,
			<7390 6774 5375 5101 5071 5063>,
			<8569 7036 5456 5083 5059 5056>,
			<12129 8125 5741 5089 5063 5060>,
			<23721 13666 7000 5102 5073 5069>,
			<23721 13666 7000 5102 5073 5069>,
			<23721 13666 7000 5102 5073 5069>;
	};

};
